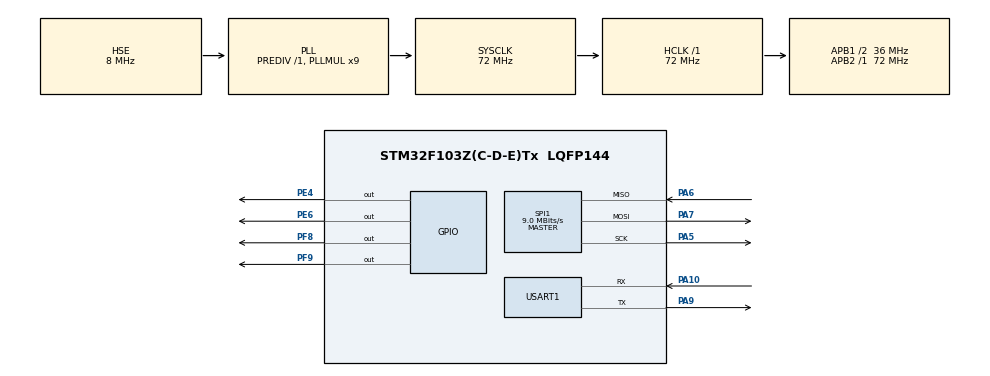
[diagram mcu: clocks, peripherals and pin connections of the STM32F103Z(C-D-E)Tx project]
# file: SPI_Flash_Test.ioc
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Mcu.Family=STM32F1
Mcu.Name=STM32F103Z(C-D-E)Tx
Mcu.Package=LQFP144
NVIC.PriorityGroup=NVIC_PRIORITYGROUP_4
OSC_IN.Mode=HSE-External-Oscillator
OSC_IN.Signal=RCC_OSC_IN
OSC_OUT.Mode=HSE-External-Oscillator
OSC_OUT.Signal=RCC_OSC_OUT
PA10.Mode=Asynchronous
PA10.Signal=USART1_RX
PA13.Mode=Serial_Wire
PA13.Signal=SYS_JTMS-SWDIO
PA14.Mode=Serial_Wire
PA14.Signal=SYS_JTCK-SWCLK
PA5.Mode=Full_Duplex_Master
PA5.Signal=SPI1_SCK
PA6.Mode=Full_Duplex_Master
PA6.Signal=SPI1_MISO
PA7.Mode=Full_Duplex_Master
PA7.Signal=SPI1_MOSI
PA9.Mode=Asynchronous
PA9.Signal=USART1_TX
PE4.PinState=GPIO_PIN_SET
PE4.Signal=GPIO_Output
PE6.PinState=GPIO_PIN_SET
PE6.Signal=GPIO_Output
PF8.GPIO_ModeDefaultOutputPP=GPIO_MODE_OUTPUT_OD
PF8.GPIO_PuPd=GPIO_NOPULL
PF8.Signal=GPIO_Output
PF9.GPIO_ModeDefaultOutputPP=GPIO_MODE_OUTPUT_OD
PF9.GPIO_PuPd=GPIO_NOPULL
PF9.Signal=GPIO_Output
ProjectManager.HeapSize=0x200
ProjectManager.StackSize=0x400
ProjectManager.TargetToolchain=MDK-ARM V5.32
RCC.AHBFreq_Value=72000000
RCC.APB1CLKDivider=RCC_HCLK_DIV2
RCC.APB1Freq_Value=36000000
RCC.APB1TimFreq_Value=72000000
RCC.APB2Freq_Value=72000000
RCC.APB2TimFreq_Value=72000000
RCC.HCLKFreq_Value=72000000
RCC.PLLMUL=RCC_PLL_MUL9
RCC.PLLSourceVirtual=RCC_PLLSOURCE_HSE
RCC.SYSCLKFreq_VALUE=72000000
RCC.SYSCLKSource=RCC_SYSCLKSOURCE_PLLCLK
RCC.USBFreq_Value=72000000
SPI1.BaudRatePrescaler=SPI_BAUDRATEPRESCALER_8
SPI1.CalculateBaudRate=9.0 MBits/s
SPI1.Direction=SPI_DIRECTION_2LINES
SPI1.Mode=SPI_MODE_MASTER
SPI1.VirtualType=VM_MASTER
USART1.Parity=PARITY_ODD
USART1.VirtualMode=VM_ASYNC
USART1.WordLength=WORDLENGTH_9B
board=custom

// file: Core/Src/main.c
/* USER CODE BEGIN Header */
/**
 ******************************************************************************
 * @file           : main.c
 * @brief          : Main program body
 ******************************************************************************
 * @attention
 *
 * Copyright (c) 2026 STMicroelectronics.
 * All rights reserved.
 *
 * This software is licensed under terms that can be found in the LICENSE file
 * in the root directory of this software component.
 * If no LICENSE file comes with this software, it is provided AS-IS.
 *
 ******************************************************************************
 */
/* USER CODE END Header */
#include "main.h"

/* USER CODE BEGIN Includes */
#include "BSP_Usart_Redir.h"
#include "App_Test.h"
/* USER CODE END Includes */

SPI_HandleTypeDef hspi1;

UART_HandleTypeDef huart1;

void SystemClock_Config(void);
static void MX_GPIO_Init(void);
static void MX_SPI1_Init(void);
static void MX_USART1_UART_Init(void);

int main(void)
{

  /* MCU Configuration--------------------------------------------------------*/

  /* Reset of all peripherals, Initializes the Flash interface and the Systick. */
  HAL_Init();

  /* Configure the system clock */
  SystemClock_Config();

  /* Initialize all configured peripherals */
  MX_GPIO_Init();
  MX_SPI1_Init();
  MX_USART1_UART_Init();
  /* USER CODE BEGIN 2 */
  BSP_Usart_Init(&huart1);

  // For test
  Test_W25Q64_Driver_Init(&hspi1, GPIOE, GPIO_PIN_6);
  Test_W25Q64_Driver_Reg1();
  Test_W25Q64_Driver_Write_Enable_Disable();
  Test_W25Q64_Driver_Erase_Read();
  Test_W25Q64_Driver_ChipErase_Any_Read_Write();
  /* USER CODE END 2 */

  /* Infinite loop */
  while (1)
  {

  }
}

void SystemClock_Config(void)
{
  RCC_OscInitTypeDef RCC_OscInitStruct = {0};
  RCC_ClkInitTypeDef RCC_ClkInitStruct = {0};

  /** Initializes the RCC Oscillators according to the specified parameters
   * in the RCC_OscInitTypeDef structure.
   */
  RCC_OscInitStruct.OscillatorType = RCC_OSCILLATORTYPE_HSE;
  RCC_OscInitStruct.HSEState = RCC_HSE_ON;
  RCC_OscInitStruct.HSEPredivValue = RCC_HSE_PREDIV_DIV1;
  RCC_OscInitStruct.HSIState = RCC_HSI_ON;
  RCC_OscInitStruct.PLL.PLLState = RCC_PLL_ON;
  RCC_OscInitStruct.PLL.PLLSource = RCC_PLLSOURCE_HSE;
  RCC_OscInitStruct.PLL.PLLMUL = RCC_PLL_MUL9;
  if (HAL_RCC_OscConfig(&RCC_OscInitStruct) != HAL_OK)
  {
    Error_Handler();
  }

  /** Initializes the CPU, AHB and APB buses clocks
   */
  RCC_ClkInitStruct.ClockType = RCC_CLOCKTYPE_HCLK | RCC_CLOCKTYPE_SYSCLK | RCC_CLOCKTYPE_PCLK1 | RCC_CLOCKTYPE_PCLK2;
  RCC_ClkInitStruct.SYSCLKSource = RCC_SYSCLKSOURCE_PLLCLK;
  RCC_ClkInitStruct.AHBCLKDivider = RCC_SYSCLK_DIV1;
  RCC_ClkInitStruct.APB1CLKDivider = RCC_HCLK_DIV2;
  RCC_ClkInitStruct.APB2CLKDivider = RCC_HCLK_DIV1;

  if (HAL_RCC_ClockConfig(&RCC_ClkInitStruct, FLASH_LATENCY_2) != HAL_OK)
  {
    Error_Handler();
  }
}

static void MX_SPI1_Init(void)
{

  /* SPI1 parameter configuration*/
  hspi1.Instance = SPI1;
  hspi1.Init.Mode = SPI_MODE_MASTER;
  hspi1.Init.Direction = SPI_DIRECTION_2LINES;
  hspi1.Init.DataSize = SPI_DATASIZE_8BIT;
  hspi1.Init.CLKPolarity = SPI_POLARITY_LOW;
  hspi1.Init.CLKPhase = SPI_PHASE_1EDGE;
  hspi1.Init.NSS = SPI_NSS_SOFT;
  hspi1.Init.BaudRatePrescaler = SPI_BAUDRATEPRESCALER_8;
  hspi1.Init.FirstBit = SPI_FIRSTBIT_MSB;
  hspi1.Init.TIMode = SPI_TIMODE_DISABLE;
  hspi1.Init.CRCCalculation = SPI_CRCCALCULATION_DISABLE;
  hspi1.Init.CRCPolynomial = 10;
  if (HAL_SPI_Init(&hspi1) != HAL_OK)
  {
    Error_Handler();
  }
}

static void MX_USART1_UART_Init(void)
{

  huart1.Instance = USART1;
  huart1.Init.BaudRate = 115200;
  huart1.Init.WordLength = UART_WORDLENGTH_9B;
  huart1.Init.StopBits = UART_STOPBITS_1;
  huart1.Init.Parity = UART_PARITY_ODD;
  huart1.Init.Mode = UART_MODE_TX_RX;
  huart1.Init.HwFlowCtl = UART_HWCONTROL_NONE;
  huart1.Init.OverSampling = UART_OVERSAMPLING_16;
  if (HAL_UART_Init(&huart1) != HAL_OK)
  {
    Error_Handler();
  }
}

static void MX_GPIO_Init(void)
{
  GPIO_InitTypeDef GPIO_InitStruct = {0};

  /* GPIO Ports Clock Enable */
  __HAL_RCC_GPIOE_CLK_ENABLE();
  __HAL_RCC_GPIOF_CLK_ENABLE();
  __HAL_RCC_GPIOA_CLK_ENABLE();

  /*Configure GPIO pin Output Level */
  HAL_GPIO_WritePin(GPIOE, GPIO_PIN_4 | GPIO_PIN_6, GPIO_PIN_SET);

  /*Configure GPIO pin Output Level */
  HAL_GPIO_WritePin(GPIOF, GPIO_PIN_8 | GPIO_PIN_9, GPIO_PIN_RESET);

  /*Configure GPIO pins : PE4 PE6 */
  GPIO_InitStruct.Pin = GPIO_PIN_4 | GPIO_PIN_6;
  GPIO_InitStruct.Mode = GPIO_MODE_OUTPUT_PP;
  GPIO_InitStruct.Pull = GPIO_NOPULL;
  GPIO_InitStruct.Speed = GPIO_SPEED_FREQ_LOW;
  HAL_GPIO_Init(GPIOE, &GPIO_InitStruct);

  /*Configure GPIO pins : PF8 PF9 */
  GPIO_InitStruct.Pin = GPIO_PIN_8 | GPIO_PIN_9;
  GPIO_InitStruct.Mode = GPIO_MODE_OUTPUT_OD;
  GPIO_InitStruct.Pull = GPIO_NOPULL;
  GPIO_InitStruct.Speed = GPIO_SPEED_FREQ_LOW;
  HAL_GPIO_Init(GPIOF, &GPIO_InitStruct);

}

void Error_Handler(void)
{
  __disable_irq();
  while (1)
  {
  }
}
